# ATmega645P device description
Architecture: AVR8; Family: megaAVR
Registers are 8-bit, access not given, no defined reset value unless marked. A register's access mark holds for its fields unless they carry their own. Offsets are from the block's base; [hi:lo] are bit positions; {n}, {i} and the like mark numbered series.

## ADC — Analog-to-Digital Converter
Instances: ADC 0x00
0x78 ADC 16-bit — ADC Data Register Bytes
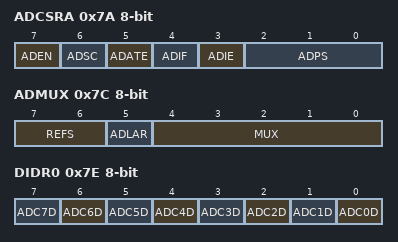
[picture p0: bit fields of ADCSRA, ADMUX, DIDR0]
0x7A ADCSRA — The ADC Control and Status register
  [7] ADEN — ADC Enable
  [6] ADSC — ADC Start Conversion
  [5] ADATE — ADC Auto Trigger Enable
  [4] ADIF — ADC Interrupt Flag
  [3] ADIE — ADC Interrupt Enable
  [2:0] ADPS — ADC Prescaler Select Bits
    0=2; 1=2; 2=4; 3=8; 4=16; 5=32; 6=64; 7=128
0x7B ADCSRB — ADC Control and Status Register B
  [2:0] ADTS — ADC Auto Trigger Sources
0x7C ADMUX — The ADC multiplexer Selection Register
  [7:6] REFS — Reference Selection Bits
    0=AREF, Internal Vref turned off; 1=AVCC with external capacitor at AREF pin; 3=Internal 1.1V Voltage Reference with external capacitor at AREF pin
  [5] ADLAR — Left Adjust Result
  [4:0] MUX — Analog Channel and Gain Selection Bits
0x7E DIDR0 — Digital Input Disable Register 0
  [n] ADC{n}D (n=0..7) — ADC{n} Digital input Disable

## AC — Analog Comparator
Instances: AC 0x00
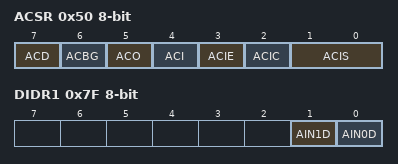
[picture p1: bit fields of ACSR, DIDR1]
0x50 ACSR — Analog Comparator Control And Status Register
  [7] ACD — Analog Comparator Disable
  [6] ACBG — Analog Comparator Bandgap Select
  [5] ACO — Analog Compare Output
  [4] ACI — Analog Comparator Interrupt Flag
  [3] ACIE — Analog Comparator Interrupt Enable
  [2] ACIC — Analog Comparator Input Capture Enable
  [1:0] ACIS — Analog Comparator Interrupt Mode Select bits
    0=Interrupt on Toggle; 2=Interrupt on Falling Edge; 3=Interrupt on Rising Edge
0x7B ADCSRB — ADC Control and Status Register B
  [6] ACME — Analog Comparator Multiplexer Enable
0x7F DIDR1 — Digital Input Disable Register 1
  [1] AIN1D — AIN1 Digital Input Disable
  [0] AIN0D — AIN0 Digital Input Disable

## SPI — Serial Peripheral Interface
Instances: SPI 0x00
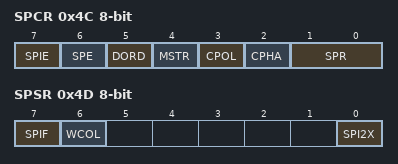
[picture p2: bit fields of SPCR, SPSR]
0x4C SPCR — SPI Control Register
  [7] SPIE — SPI Interrupt Enable
  [6] SPE — SPI Enable
  [5] DORD — Data Order
  [4] MSTR — Master/Slave Select
  [3] CPOL — Clock polarity
  [2] CPHA — Clock Phase
  [1:0] SPR — SPI Clock Rate Selects
    0=fosc/4; 1=fosc/16; 2=fosc/64; 3=fosc/128; 4=fosc/2; 5=fosc/8; 6=fosc/32; 7=fosc/64
0x4D SPSR — SPI Status Register
  [7] SPIF — SPI Interrupt Flag
  [6] WCOL — Write Collision Flag
  [0] SPI2X — Double SPI Speed Bit
0x4E SPDR — SPI Data Register

## USI — Universal Serial Interface
Instances: USI 0x00
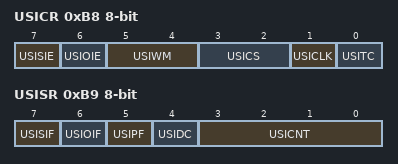
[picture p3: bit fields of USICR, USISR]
0xB8 USICR — USI Control Register
  [7] USISIE — Start Condition Interrupt Enable
  [6] USIOIE — Counter Overflow Interrupt Enable
  [5:4] USIWM — USI Wire Mode Bits
    0=Normal Operation; 1=Three-Wire Mode; 2=Two-Wire Mode; 3=Two-Wire Mode Held Low
  [3:2] USICS — USI Clock Source Select Bits
  [1] USICLK — Clock Strobe
  [0] USITC — Toggle Clock Port Pin
0xB9 USISR — USI Status Register
  [7] USISIF — Start Condition Interrupt Flag
  [6] USIOIF — Counter Overflow Interrupt Flag
  [5] USIPF — Stop Condition Flag
  [4] USIDC — Data Output Collision
  [3:0] USICNT — USI Counter Value Bits
0xBA USIDR — USI Data Register

## CPU — CPU Registers
Instances: CPU 0x00
Parameters: CORE_VERSION=V2E
0x3E GPIOR0 — General Purpose IO Register 0
0x4A GPIOR1 — General Purpose IO Register 1
0x4B GPIOR2 — General Purpose IO Register 2
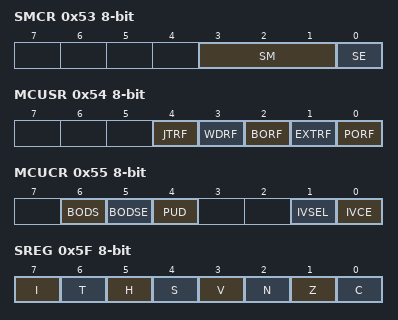
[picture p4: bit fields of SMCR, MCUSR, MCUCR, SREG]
0x53 SMCR — Sleep Mode Control Register
  [3:1] SM — Sleep Mode Select bits
    0=IDLE; 1=ADC (ADC Noise Reduction (If Available)); 2=PDOWN (Power Down); 3=PSAVE (Power Save); 6=STDBY (Standby)
  [0] SE — Sleep Enable
0x54 MCUSR — MCU Status Register
  [4] JTRF — JTAG Reset Flag
  [3] WDRF — Watchdog Reset Flag
  [2] BORF — Brown-out Reset Flag
  [1] EXTRF — External Reset Flag
  [0] PORF — Power-on reset flag
0x55 MCUCR — MCU Control Register
  [6] BODS — BOD Sleep
  [5] BODSE — BOD Sleep Enable
  [4] PUD — Pull-up disable
  [1] IVSEL — Interrupt Vector Select
  [0] IVCE — Interrupt Vector Change Enable
0x5D SP 16-bit — Stack Pointer
0x5F SREG — Status Register
  [7] I — Global Interrupt Enable
  [6] T — Bit Copy Storage
  [5] H — Half Carry Flag
  [4] S — Sign Bit
  [3] V — Two's Complement Overflow Flag
  [2] N — Negative Flag
  [1] Z — Zero Flag
  [0] C — Carry Flag
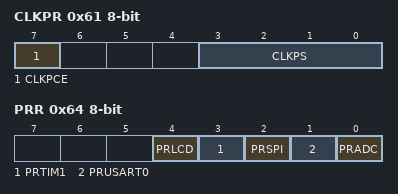
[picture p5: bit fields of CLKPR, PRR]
0x61 CLKPR — Clock Prescale Register
  [7] CLKPCE — Clock Prescaler Change Enable
  [3:0] CLKPS — Clock Prescaler Select Bits
    0=1; 1=2; 2=4; 3=8; 4=16; 5=32; 6=64; 7=128; 8=256
0x64 PRR — Power Reduction Register
  [4] PRLCD — Power Reduction LCD
  [3] PRTIM1 — Power Reduction Timer/Counter1
  [2] PRSPI — Power Reduction Serial Peripheral Interface
  [1] PRUSART0 — Power Reduction USART
  [0] PRADC — Power Reduction ADC
0x66 OSCCAL — Oscillator Calibration Value
  [7:0] OSCCAL — Oscillator Calibration
Value list OSCCAL_VALUE_ADDRESSES: 0=8_0_MHz
